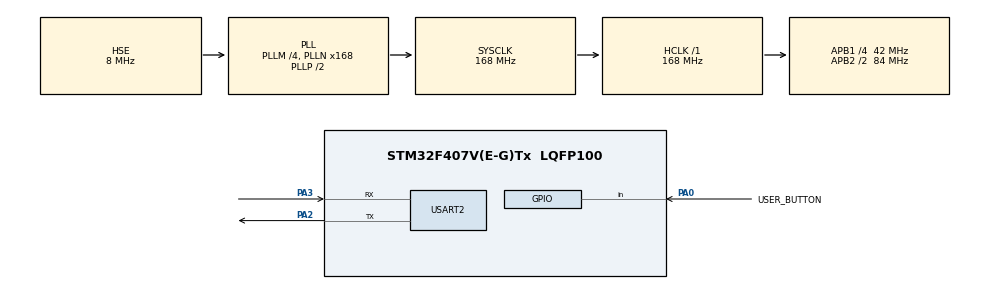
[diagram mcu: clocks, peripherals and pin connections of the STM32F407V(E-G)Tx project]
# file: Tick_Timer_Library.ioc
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Mcu.Family=STM32F4
Mcu.Name=STM32F407V(E-G)Tx
Mcu.Package=LQFP100
NVIC.PriorityGroup=NVIC_PRIORITYGROUP_0
NVIC.TIM2_IRQn=true\:0\:0\:false\:false\:true\:true\:true\:true
PA0-WKUP.GPIO_Label=USER_BUTTON
PA0-WKUP.Signal=GPIO_Input
PA2.Mode=Asynchronous
PA2.Signal=USART2_TX
PA3.Mode=Asynchronous
PA3.Signal=USART2_RX
PH0-OSC_IN.Mode=HSE-External-Oscillator
PH0-OSC_IN.Signal=RCC_OSC_IN
PH1-OSC_OUT.Mode=HSE-External-Oscillator
PH1-OSC_OUT.Signal=RCC_OSC_OUT
ProjectManager.HeapSize=0x200
ProjectManager.StackSize=0x400
ProjectManager.TargetToolchain=STM32CubeIDE
RCC.48MHZClocksFreq_Value=48000000
RCC.AHBFreq_Value=168000000
RCC.APB1CLKDivider=RCC_HCLK_DIV4
RCC.APB1Freq_Value=42000000
RCC.APB1TimFreq_Value=84000000
RCC.APB2CLKDivider=RCC_HCLK_DIV2
RCC.APB2Freq_Value=84000000
RCC.APB2TimFreq_Value=168000000
RCC.CortexFreq_Value=168000000
RCC.HCLKFreq_Value=168000000
RCC.HSE_VALUE=8000000
RCC.HSI_VALUE=16000000
RCC.LSE_VALUE=32768
RCC.PLLM=4
RCC.PLLN=168
RCC.PLLQ=7
RCC.PLLSourceVirtual=RCC_PLLSOURCE_HSE
RCC.SYSCLKFreq_VALUE=168000000
RCC.SYSCLKSource=RCC_SYSCLKSOURCE_PLLCLK
RCC.VCOOutputFreq_Value=336000000
TIM2.Period=999
TIM2.Prescaler=83
USART2.VirtualMode=VM_ASYNC
VP_TIM2_VS_ClockSourceINT.Mode=Internal
board=STM32F407G-DISC1

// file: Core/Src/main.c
/* USER CODE BEGIN Header */
/**
  ******************************************************************************
  * @file           : main.c
  * @brief          : Main program body
  ******************************************************************************
  * @attention
  *
  * Copyright (c) 2025 STMicroelectronics.
  * All rights reserved.
  *
  * This software is licensed under terms that can be found in the LICENSE file
  * in the root directory of this software component.
  * If no LICENSE file comes with this software, it is provided AS-IS.
  *
  ******************************************************************************
  */
/* USER CODE END Header */
#include "main.h"

/* USER CODE BEGIN Includes */
#include <string.h>
#include "tick_timer_driver.h"

/* USER CODE END Includes */

/* USER CODE BEGIN PTD */

typedef struct{
	GPIO_TypeDef 		*GPIOx;
	uint16_t 			GPIO_Pin;
	GPIO_PinState		inputState;
	Software_Timer_t    debounceTimer;
	uint32_t 			debounceTime;
}Input_Info_t;

/* USER CODE END PTD */

TIM_HandleTypeDef htim2;

UART_HandleTypeDef huart2;

/* USER CODE BEGIN PV */

uint8_t second, minute, hour;
Software_Timer_t time1s;

Input_Info_t gpioA_Pin0;

Software_Timer_t messageTime;
Software_Timer_t messageStopTime;

Software_Timer_t softwareTasks[4];
/* USER CODE END PV */

void SystemClock_Config(void);
static void MX_GPIO_Init(void);
static void MX_TIM2_Init(void);
static void MX_USART2_UART_Init(void);
/* USER CODE BEGIN PFP */

void IO_Debounce_Control(Input_Info_t *inputInfo);
void UART_Send_Message(void);
void Stop_Uart_Message(void);
/* USER CODE END PFP */

/* USER CODE BEGIN 0 */
void Clock_Task(void)
{
	second++;
	if(second >= 60)
	{
		second = 0;
		minute++;
		if(minute >= 60)
		{
			minute = 0;
			hour++;
			if(hour >= 24)
			{
				hour = 0;

			}
		}
	}

}

void IO_Debounce_Control(Input_Info_t *inputInfo)
{
	GPIO_PinState currentState = HAL_GPIO_ReadPin(inputInfo->GPIOx, inputInfo->GPIO_Pin);

	if(currentState == GPIO_PIN_SET)
	{
		if(inputInfo->inputState != GPIO_PIN_SET)
		{
			if(inputInfo->debounceTimer.timerInfo.active == false)
			{
				Tick_Timer_Create(&inputInfo->debounceTimer, inputInfo->debounceTime, TIMER_TYPE_ONESHOT, NULL);
				Tick_Timer_Start(&inputInfo->debounceTimer);
			}
			if(Tick_Timer_Check_Elapsed_Time(&inputInfo->debounceTimer))
			{
				inputInfo->inputState = GPIO_PIN_SET;

				if(messageTime.timerInfo.active != true)
				{
					Tick_Timer_Create(&messageTime, 1000, TIMER_TYPE_PERIODIC, UART_Send_Message);
					Tick_Timer_Start(&messageTime);
				}
			}
		}

	}
	else
	{
		inputInfo->inputState = GPIO_PIN_RESET;
		Tick_Timer_Stop(&inputInfo->debounceTimer);
	}
}

void Stop_Uart_Message(void)
{
	Tick_Timer_Stop(&messageTime);
}

void UART_Send_Message(void)
{
	const char *msg = "Reaktif Mesaj Fonksiyonu Calisiyor... \r\n";
	HAL_UART_Transmit(&huart2, (uint8_t*)msg, strlen(msg), HAL_MAX_DELAY);

	if(messageStopTime.timerInfo.active == false)
	{
		Tick_Timer_Create(&messageStopTime, 10000, TIMER_TYPE_ONESHOT, Stop_Uart_Message);
		Tick_Timer_Start(&messageStopTime);
	}
}

void Task1_Control(void)
{
	const char *msg = "Task1 Calisti \r\n";
	HAL_UART_Transmit(&huart2, (uint8_t*)msg, strlen(msg), HAL_MAX_DELAY);
}

void Task2_Control(void)
{
	Clock_Task();
	const char *msg = "Task2 Calisti \r\n";
	char buffer[50];
	sprintf(buffer, "Zaman: %d:%d:%d: \r\n", hour, minute, second);
	HAL_UART_Transmit(&huart2, (uint8_t*)msg, strlen(msg), HAL_MAX_DELAY);
	HAL_UART_Transmit(&huart2, (uint8_t*)buffer, strlen(msg), HAL_MAX_DELAY);
}

void Task3_Control(void)
{
	const char *msg = "Task3 Calisti \r\n";
	HAL_UART_Transmit(&huart2, (uint8_t*)msg, strlen(msg), HAL_MAX_DELAY);
}

void Task4_Control(void)
{
	const char *msg = "Task4 Calisti \r\n";
	HAL_UART_Transmit(&huart2, (uint8_t*)msg, strlen(msg), HAL_MAX_DELAY);
}

/* USER CODE END 0 */

int main(void)
{

  /* MCU Configuration--------------------------------------------------------*/

  /* Reset of all peripherals, Initializes the Flash interface and the Systick. */
  HAL_Init();

  /* Configure the system clock */
  SystemClock_Config();

  /* Initialize all configured peripherals */
  MX_GPIO_Init();
  MX_TIM2_Init();
  MX_USART2_UART_Init();
  /* USER CODE BEGIN 2 */
  Tick_Timer_Init(&htim2);

  /*
  Tick_Timer_Create(&time1s, 1000, TIMER_TYPE_PERIODIC, Clock_Task);
  Tick_Timer_Start(&time1s);

  gpioA_Pin0.GPIOx         = USER_BUTTON_GPIO_Port;
  gpioA_Pin0.GPIO_Pin      = USER_BUTTON_Pin;
  gpioA_Pin0.debounceTime  = 200;
  */

  Tick_Timer_Create(&softwareTasks[0], 500,  TIMER_TYPE_PERIODIC, Task1_Control);
  Tick_Timer_Create(&softwareTasks[1], 1000, TIMER_TYPE_PERIODIC, Task2_Control);
  Tick_Timer_Create(&softwareTasks[2], 2000, TIMER_TYPE_PERIODIC, Task3_Control);
  Tick_Timer_Create(&softwareTasks[3], 5000, TIMER_TYPE_PERIODIC, Task4_Control);

  Tick_Timer_Start(&softwareTasks[0]);
  Tick_Timer_Start(&softwareTasks[1]);
  Tick_Timer_Start(&softwareTasks[2]);
  Tick_Timer_Start(&softwareTasks[3]);

  /* USER CODE END 2 */

  /* Infinite loop */
  while (1)
  {

    /* USER CODE BEGIN 3 */

	  for(int i = 0; i < 4; i++)
		  Tick_Timer_Check_Elapsed_Time(&softwareTasks[i]);

	  /*
	  Tick_Timer_Check_Elapsed_Time(&time1s);
	  Tick_Timer_Check_Elapsed_Time(&messageTime);
	  Tick_Timer_Check_Elapsed_Time(&messageStopTime);
	  IO_Debounce_Control(&gpioA_Pin0);
	  */
  }
  /* USER CODE END 3 */
}

void SystemClock_Config(void)
{
  RCC_OscInitTypeDef RCC_OscInitStruct = {0};
  RCC_ClkInitTypeDef RCC_ClkInitStruct = {0};

  /** Configure the main internal regulator output voltage
  */
  __HAL_RCC_PWR_CLK_ENABLE();
  __HAL_PWR_VOLTAGESCALING_CONFIG(PWR_REGULATOR_VOLTAGE_SCALE1);

  /** Initializes the RCC Oscillators according to the specified parameters
  * in the RCC_OscInitTypeDef structure.
  */
  RCC_OscInitStruct.OscillatorType = RCC_OSCILLATORTYPE_HSE;
  RCC_OscInitStruct.HSEState = RCC_HSE_ON;
  RCC_OscInitStruct.PLL.PLLState = RCC_PLL_ON;
  RCC_OscInitStruct.PLL.PLLSource = RCC_PLLSOURCE_HSE;
  RCC_OscInitStruct.PLL.PLLM = 4;
  RCC_OscInitStruct.PLL.PLLN = 168;
  RCC_OscInitStruct.PLL.PLLP = RCC_PLLP_DIV2;
  RCC_OscInitStruct.PLL.PLLQ = 7;
  if (HAL_RCC_OscConfig(&RCC_OscInitStruct) != HAL_OK)
  {
    Error_Handler();
  }

  /** Initializes the CPU, AHB and APB buses clocks
  */
  RCC_ClkInitStruct.ClockType = RCC_CLOCKTYPE_HCLK|RCC_CLOCKTYPE_SYSCLK
                              |RCC_CLOCKTYPE_PCLK1|RCC_CLOCKTYPE_PCLK2;
  RCC_ClkInitStruct.SYSCLKSource = RCC_SYSCLKSOURCE_PLLCLK;
  RCC_ClkInitStruct.AHBCLKDivider = RCC_SYSCLK_DIV1;
  RCC_ClkInitStruct.APB1CLKDivider = RCC_HCLK_DIV4;
  RCC_ClkInitStruct.APB2CLKDivider = RCC_HCLK_DIV2;

  if (HAL_RCC_ClockConfig(&RCC_ClkInitStruct, FLASH_LATENCY_5) != HAL_OK)
  {
    Error_Handler();
  }
}

static void MX_TIM2_Init(void)
{

  TIM_ClockConfigTypeDef sClockSourceConfig = {0};
  TIM_MasterConfigTypeDef sMasterConfig = {0};

  htim2.Instance = TIM2;
  htim2.Init.Prescaler = 83;
  htim2.Init.CounterMode = TIM_COUNTERMODE_UP;
  htim2.Init.Period = 999;
  htim2.Init.ClockDivision = TIM_CLOCKDIVISION_DIV1;
  htim2.Init.AutoReloadPreload = TIM_AUTORELOAD_PRELOAD_DISABLE;
  if (HAL_TIM_Base_Init(&htim2) != HAL_OK)
  {
    Error_Handler();
  }
  sClockSourceConfig.ClockSource = TIM_CLOCKSOURCE_INTERNAL;
  if (HAL_TIM_ConfigClockSource(&htim2, &sClockSourceConfig) != HAL_OK)
  {
    Error_Handler();
  }
  sMasterConfig.MasterOutputTrigger = TIM_TRGO_RESET;
  sMasterConfig.MasterSlaveMode = TIM_MASTERSLAVEMODE_DISABLE;
  if (HAL_TIMEx_MasterConfigSynchronization(&htim2, &sMasterConfig) != HAL_OK)
  {
    Error_Handler();
  }

}

static void MX_USART2_UART_Init(void)
{

  huart2.Instance = USART2;
  huart2.Init.BaudRate = 115200;
  huart2.Init.WordLength = UART_WORDLENGTH_8B;
  huart2.Init.StopBits = UART_STOPBITS_1;
  huart2.Init.Parity = UART_PARITY_NONE;
  huart2.Init.Mode = UART_MODE_TX_RX;
  huart2.Init.HwFlowCtl = UART_HWCONTROL_NONE;
  huart2.Init.OverSampling = UART_OVERSAMPLING_16;
  if (HAL_UART_Init(&huart2) != HAL_OK)
  {
    Error_Handler();
  }

}

static void MX_GPIO_Init(void)
{
  GPIO_InitTypeDef GPIO_InitStruct = {0};

  /* GPIO Ports Clock Enable */
  __HAL_RCC_GPIOH_CLK_ENABLE();
  __HAL_RCC_GPIOA_CLK_ENABLE();

  /*Configure GPIO pin : USER_BUTTON_Pin */
  GPIO_InitStruct.Pin = USER_BUTTON_Pin;
  GPIO_InitStruct.Mode = GPIO_MODE_INPUT;
  GPIO_InitStruct.Pull = GPIO_NOPULL;
  HAL_GPIO_Init(USER_BUTTON_GPIO_Port, &GPIO_InitStruct);

}

void Error_Handler(void)
{
  __disable_irq();
  while (1)
  {
  }
}
